# cslr_vfoc_001 register map
Vendor: Texas Instruments
Peripheral module from a debugger description file.
Registers are 32-bit, access per field, reset 0x0 unless marked. A register's access mark holds for its fields unless they carry their own. Offsets are as the file gives them; lines under a group give offsets from that group; [hi:lo] are bit positions; {n}, {i} and the like mark numbered series; 'fields as' and 'values as' point back to an identical list; <NAME> marks a mode.

## VFOC — VFocus to compute focus metrics (spec version: 1.00.w.04)
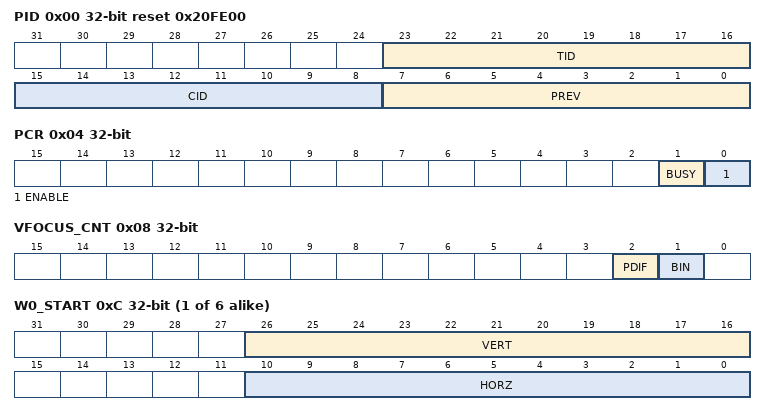
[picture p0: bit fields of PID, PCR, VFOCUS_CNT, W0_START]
0x00 PID ro reset 0x20FE00 — Peripheral Revision and Class Information
  [23:16] TID — \hPeripheral Identification. VFocus module
  [15:8] CID — \hClass Identification. Video processing front end
  [7:0] PREV — \hPeripheral Revision Number. Initial Revision
0x04 PCR — Peripheral Control Register
  [1] BUSY ro — \hBusy
    0=NOTBUSY (VFocus module is not busy); 1=BUSY (VFocus module is busy)
  [0] ENABLE rw — \hEnable
    0=DISABLE (Disable VFocus module); 1=ENABLE (Enable VFocus module)
0x08 VFOCUS_CNT — VFocus control bits
  [2] PDIF rw — \hSelect abs(1-3) or abs(1-5) . Line'1' corresponds to the uppermost line in the 5x1 grid, Line'3' is the middle line and Line'5' is the lowermost line. Therefore, Line'1' is the earliest line clocked out from a sensor point of view assuming the image is being read out from top to bottom
    0=ABS_1TO3 (|1-3|); 1=ABS_1TO5 (|1-5|)
  [1] BIN rw — \hHorizontal binning (0 or 2) . If binning is enabled, then the window sizing below follow the post-binning count. Therefore, if the original horizontal count was 32, horizontal binning reduces the count to 16. Now if a window is set as start horizontally at 0 and end at 10, then the settings correspond to the binned frame.
    0=NOBIN (Don't bin); 1=AVG_2LIKECOLOR_PIXELSH (Average two same color pixels horizontally)
{0xC+8i} W{i}_START (i=0..5) — Window {i} start information
  [26:16] VERT rw — Starting position of window {i} in the vertical direction
  [10:0] HORZ rw — Starting position of Window {i} in the horizontal direction
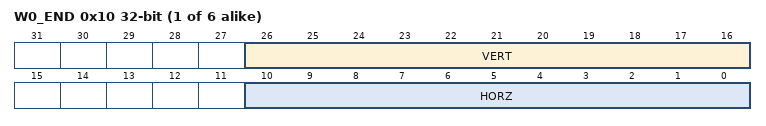
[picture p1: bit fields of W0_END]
{0x10+8i} W{i}_END (i=0..5) — Window {i} end information
  [26:16] VERT rw — Ending position of window {i} in the vertical direction . If the end is programmed as the same value of start, then the window size is treated as 0. In all cases, the total number of pixels processed is End - Start + 1. Therefore, the minimum window dimension is at least 2.
  [10:0] HORZ rw — Ending position of Window {i} in the horizontal direction . If the end is programmed as the same value of start, then the window size is treated as 0. In all cases, the total number of pixels processed is End - Start + 1. Therefore, the minimum window dimension is at least 2.
{0x3C+0x18*i} W{i}_ACCL_R rw reset not defined (i=0..5) — Window {i} - Accumulator for Red (lower 32-bits)
  [31:0] W{i}_ACCL_R — Accumulated value
{0x40+0x18*i} W{i}_ACCU_R (reset mask 0xFFFFFF00) (i=0..5) — Window {i} - Accumulator for Red (upper 8-bits)
  [7:0] ACC rw — Accumulated value
{0x44+0x18*i} W{i}_ACCL_G rw reset not defined (i=0..5) — Window {i} - Accumulator for Green (lower 32-bits)
  [31:0] W{i}_ACCL_G — Accumulated value
{0x48+0x18*i} W{i}_ACCU_G (reset mask 0xFFFFFF00) (i=0..5) — Window {i} - Accumulator for Green (upper 8-bits)
  [7:0] ACC rw — Accumulated value
{0x4C+0x18*i} W{i}_ACCL_B rw reset not defined (i=0..5) — Window {i} - Accumulator for Blue (lower 32-bits)
  [31:0] W{i}_ACCL_B — Accumulated value
{0x50+0x18*i} W{i}_ACCU_B (reset mask 0xFFFFFF00) (i=0..5) — Window {i} - Accumulator for Blue (upper 8-bits)
  [7:0] ACC rw — Accumulated value
{0xCC+4i} LUT{i} (reset mask 0xFF000000) (i=0..63) — Lut entry {i}
  [23:0] LUT{i} rw — LUT entry {i}
